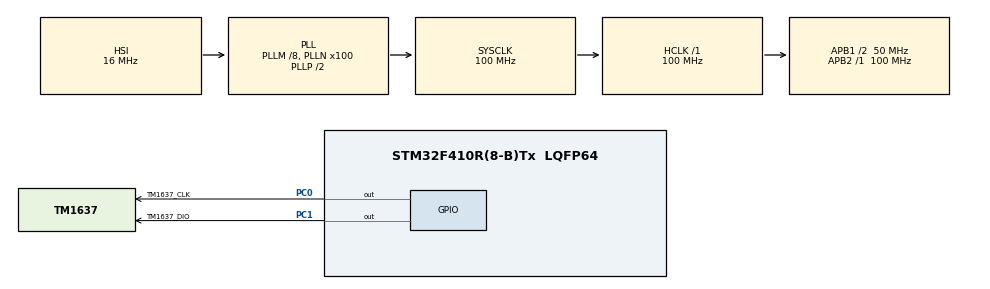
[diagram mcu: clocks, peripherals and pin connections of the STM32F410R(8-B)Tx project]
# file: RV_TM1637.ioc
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Mcu.Family=STM32F4
Mcu.Name=STM32F410R(8-B)Tx
Mcu.Package=LQFP64
NVIC.PriorityGroup=NVIC_PRIORITYGROUP_0
PC0.GPIO_Label=TM1637_CLK
PC0.GPIO_ModeDefaultOutputPP=GPIO_MODE_OUTPUT_OD
PC0.GPIO_PuPd=GPIO_PULLUP
PC0.Signal=GPIO_Output
PC1.GPIO_Label=TM1637_DIO
PC1.GPIO_ModeDefaultOutputPP=GPIO_MODE_OUTPUT_OD
PC1.GPIO_PuPd=GPIO_PULLUP
PC1.Signal=GPIO_Output
ProjectManager.HeapSize=0x200
ProjectManager.StackSize=0x400
ProjectManager.TargetToolchain=MDK-ARM V5
RCC.48MHZClocksFreq_Value=50000000
RCC.AHBFreq_Value=100000000
RCC.APB1CLKDivider=RCC_HCLK_DIV2
RCC.APB1Freq_Value=50000000
RCC.APB1TimFreq_Value=100000000
RCC.APB2Freq_Value=100000000
RCC.APB2TimFreq_Value=100000000
RCC.CortexFreq_Value=100000000
RCC.FLatency-AdvancedSettings=FLASH_LATENCY_3
RCC.HCLKFreq_Value=100000000
RCC.HSE_VALUE=8000000
RCC.HSI_VALUE=16000000
RCC.LSE_VALUE=32768
RCC.PLLM=8
RCC.PLLN=100
RCC.SYSCLKFreq_VALUE=100000000
RCC.SYSCLKSource=RCC_SYSCLKSOURCE_PLLCLK
RCC.VCOOutputFreq_Value=200000000
board=NUCLEO-F410RB

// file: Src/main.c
/* USER CODE BEGIN Header */
/**
  ******************************************************************************
  * @file           : main.c
  * @brief          : Main program body
  ******************************************************************************
  ** This notice applies to any and all portions of this file
  * that are not between comment pairs USER CODE BEGIN and
  * USER CODE END. Other portions of this file, whether
  * inserted by the user or by software development tools
  * are owned by their respective copyright owners.
  *
  * COPYRIGHT(c) 2018 STMicroelectronics
  *
  * Redistribution and use in source and binary forms, with or without modification,
  * are permitted provided that the following conditions are met:
  *   1. Redistributions of source code must retain the above copyright notice,
  *      this list of conditions and the following disclaimer.
  *   2. Redistributions in binary form must reproduce the above copyright notice,
  *      this list of conditions and the following disclaimer in the documentation
  *      and/or other materials provided with the distribution.
  *   3. Neither the name of STMicroelectronics nor the names of its contributors
  *      may be used to endorse or promote products derived from this software
  *      without specific prior written permission.
  *
  * THIS SOFTWARE IS PROVIDED BY THE COPYRIGHT HOLDERS AND CONTRIBUTORS "AS IS"
  * AND ANY EXPRESS OR IMPLIED WARRANTIES, INCLUDING, BUT NOT LIMITED TO, THE
  * IMPLIED WARRANTIES OF MERCHANTABILITY AND FITNESS FOR A PARTICULAR PURPOSE ARE
  * DISCLAIMED. IN NO EVENT SHALL THE COPYRIGHT HOLDER OR CONTRIBUTORS BE LIABLE
  * FOR ANY DIRECT, INDIRECT, INCIDENTAL, SPECIAL, EXEMPLARY, OR CONSEQUENTIAL
  * DAMAGES (INCLUDING, BUT NOT LIMITED TO, PROCUREMENT OF SUBSTITUTE GOODS OR
  * SERVICES; LOSS OF USE, DATA, OR PROFITS; OR BUSINESS INTERRUPTION) HOWEVER
  * CAUSED AND ON ANY THEORY OF LIABILITY, WHETHER IN CONTRACT, STRICT LIABILITY,
  * OR TORT (INCLUDING NEGLIGENCE OR OTHERWISE) ARISING IN ANY WAY OUT OF THE USE
  * OF THIS SOFTWARE, EVEN IF ADVISED OF THE POSSIBILITY OF SUCH DAMAGE.
  *
  ******************************************************************************
  */
/* USER CODE END Header */

#include "main.h"

/* USER CODE BEGIN Includes */
#include "RV_TM1637.h"
/* USER CODE END Includes */

void SystemClock_Config(void);
static void MX_GPIO_Init(void);

int main(void)
{

  /* MCU Configuration--------------------------------------------------------*/

  /* Reset of all peripherals, Initializes the Flash interface and the Systick. */
  HAL_Init();

  /* Configure the system clock */
  SystemClock_Config();

  /* Initialize all configured peripherals */
  MX_GPIO_Init();
  /* USER CODE BEGIN 2 */
	RV_TM1637 disp(TM1637_CLK_GPIO_Port, TM1637_CLK_Pin, TM1637_DIO_GPIO_Port, TM1637_DIO_Pin);
	disp.clear();
	disp.brightness(3);

	for (int i = -999; i <= 9999; i++) {
		disp.displayInt(i);
		HAL_Delay(5);
	}

	disp.point(POINT_ON);
	disp.displayClock(4, 3);
	HAL_Delay(1000);
	disp.point(POINT_OFF);
	disp.displayClock(12, 30);
	HAL_Delay(1000);
	disp.point(POINT_ON);
	disp.displayClock(12, 31);
	HAL_Delay(1000);
	disp.point(POINT_OFF);

	disp.display(0, 1, 2, 3);
	HAL_Delay(1000);

	disp.displayByte(_A, _B, _C, _D);
	HAL_Delay(1000);

	uint8_t data[4] = {4, 5, 6, 7};
	disp.display(data);
	HAL_Delay(1000);

	uint8_t dataB[4] = {_E, _F, _G, _H};
	disp.displayByte(dataB);
	HAL_Delay(1000);

	disp.display(0, 8);
	disp.display(1, 9);
	HAL_Delay(1000);

	disp.displayByte(2, _A);
	disp.displayByte(3, _E);
	HAL_Delay(1000);

	for (uint8_t i = 0; i <=7; i++) {
		disp.brightness(i);
		HAL_Delay(500);
	}
	disp.brightness(3);

	disp.clear();
	HAL_Delay(1000);

	uint8_t str[8] = {_D, _E, _M, _O, _empty, _E, _N, _D};
	disp.runningString(str, 8, 500);
  /* USER CODE END 2 */

  /* Infinite loop */
  while (1)
  {

  }
}

void SystemClock_Config(void)
{
  RCC_OscInitTypeDef RCC_OscInitStruct = {0};
  RCC_ClkInitTypeDef RCC_ClkInitStruct = {0};

  /**Configure the main internal regulator output voltage
  */
  __HAL_RCC_PWR_CLK_ENABLE();
  __HAL_PWR_VOLTAGESCALING_CONFIG(PWR_REGULATOR_VOLTAGE_SCALE1);
  /**Initializes the CPU, AHB and APB busses clocks
  */
  RCC_OscInitStruct.OscillatorType = RCC_OSCILLATORTYPE_HSI;
  RCC_OscInitStruct.HSIState = RCC_HSI_ON;
  RCC_OscInitStruct.HSICalibrationValue = RCC_HSICALIBRATION_DEFAULT;
  RCC_OscInitStruct.PLL.PLLState = RCC_PLL_ON;
  RCC_OscInitStruct.PLL.PLLSource = RCC_PLLSOURCE_HSI;
  RCC_OscInitStruct.PLL.PLLM = 8;
  RCC_OscInitStruct.PLL.PLLN = 100;
  RCC_OscInitStruct.PLL.PLLP = RCC_PLLP_DIV2;
  RCC_OscInitStruct.PLL.PLLQ = 4;
  RCC_OscInitStruct.PLL.PLLR = 2;
  if (HAL_RCC_OscConfig(&RCC_OscInitStruct) != HAL_OK)
  {
    Error_Handler();
  }
  /**Initializes the CPU, AHB and APB busses clocks
  */
  RCC_ClkInitStruct.ClockType = RCC_CLOCKTYPE_HCLK|RCC_CLOCKTYPE_SYSCLK
                              |RCC_CLOCKTYPE_PCLK1|RCC_CLOCKTYPE_PCLK2;
  RCC_ClkInitStruct.SYSCLKSource = RCC_SYSCLKSOURCE_PLLCLK;
  RCC_ClkInitStruct.AHBCLKDivider = RCC_SYSCLK_DIV1;
  RCC_ClkInitStruct.APB1CLKDivider = RCC_HCLK_DIV2;
  RCC_ClkInitStruct.APB2CLKDivider = RCC_HCLK_DIV1;

  if (HAL_RCC_ClockConfig(&RCC_ClkInitStruct, FLASH_LATENCY_3) != HAL_OK)
  {
    Error_Handler();
  }
}

static void MX_GPIO_Init(void)
{
  GPIO_InitTypeDef GPIO_InitStruct = {0};

  /* GPIO Ports Clock Enable */
  __HAL_RCC_GPIOC_CLK_ENABLE();

  /*Configure GPIO pin Output Level */
  HAL_GPIO_WritePin(GPIOC, TM1637_CLK_Pin|TM1637_DIO_Pin, GPIO_PIN_RESET);

  /*Configure GPIO pins : TM1637_CLK_Pin TM1637_DIO_Pin */
  GPIO_InitStruct.Pin = TM1637_CLK_Pin|TM1637_DIO_Pin;
  GPIO_InitStruct.Mode = GPIO_MODE_OUTPUT_OD;
  GPIO_InitStruct.Pull = GPIO_PULLUP;
  GPIO_InitStruct.Speed = GPIO_SPEED_FREQ_LOW;
  HAL_GPIO_Init(GPIOC, &GPIO_InitStruct);

}

void Error_Handler(void)
{
}

/************************ (C) COPYRIGHT STMicroelectronics *****END OF FILE****/
